# GD32VW553x register map
File version: 1.0
CPU: other RISC-V, little endian, no MPU, FPU
Registers are 32-bit, read-write, reset 0x0 unless marked. A register's access mark holds for its fields unless they carry their own. Offsets are from the block's base; [hi:lo] are bit positions; {n}, {i} and the like mark numbered series.

## FMC — Flash memory controller
Base 0x40022000
0x04 KEY wo — Unlock key register
  [31:0] KEY — FMC_CTL unlock register
0x08 OBKEY wo — Option byte unlock key register
  [31:0] OBKEY — These bits are only be written by software
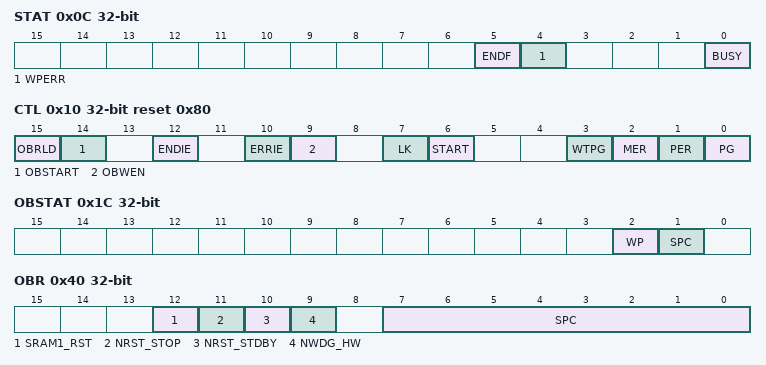
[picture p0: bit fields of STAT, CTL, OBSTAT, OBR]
0x0C STAT access per field — Status register
  [5] ENDF rw — End of operation flag bit
  [4] WPERR rw — Erase / Program protection error flag bit
  [0] BUSY ro — The flash is busy bit
0x10 CTL access per field reset 0x80 — Control register
  [15] OBRLD rw — Option byte reload bit
  [14] OBSTART rw — Option bytes modification start bit
  [12] ENDIE rw — End of operation interrupt enable bit
  [10] ERRIE rw — Error interrupt enable bit
  [9] OBWEN rw — FMC option byte registers write enable bit
  [7] LK ro — FMC_CTL lock bit
  [6] START ro — Send erase command to FMC
  [3] WTPG rw — WIFI trim program command bit
  [2] MER rw — Main flash mass erase command bit
  [1] PER rw — Main flash page erase command bit
  [0] PG rw — Main flash program command bit
0x14 ADDR wo — Address register
  [31:0] ADDR — Flash erase / program command address bits
0x1C OBSTAT ro — Option byte status register
  [2] WP — Write/erase protection state, EFFUSE config 32k write protection
  [1] SPC — Security protection level 1 state
0x40 OBR — Option byte register
  [12] SRAM1_RST — SRAM1 reset enable bit
  [11] NRST_STOP — Vcore domain Stop entry reset option status bit
  [10] NRST_STDBY — Vcore domain Standby entry reset option status bit
  [9] NWDG_HW — IWDG option byte
  [7:0] SPC — Option byte security protection value
0x44 OBUSER — Option byte user value register
  [31:0] USER — Option byte USER value
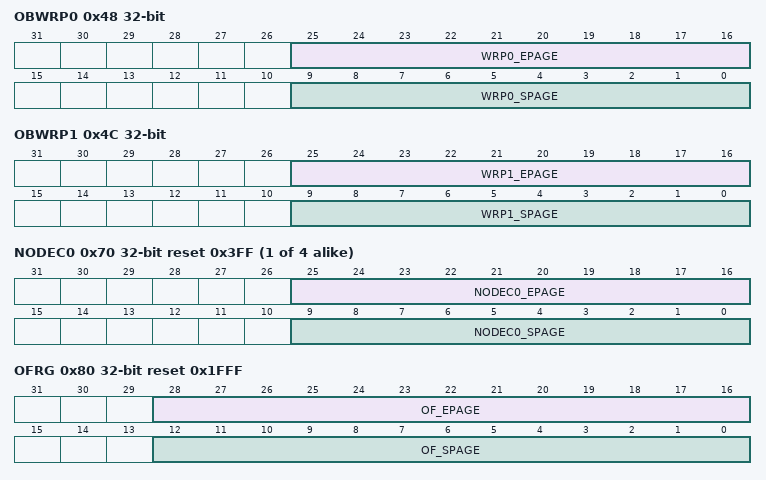
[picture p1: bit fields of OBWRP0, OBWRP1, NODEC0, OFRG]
0x48 OBWRP0 — Option byte write protection area register 0
  [25:16] WRP0_EPAGE — End page of write protection area 0
  [9:0] WRP0_SPAGE — Start page of write protection area 0
0x4C OBWRP1 — Option byte write protection area register 1
  [25:16] WRP1_EPAGE — End page of write protection area 1
  [9:0] WRP1_SPAGE — Start page of write protection area 1
{0x70+4i} NODEC{i} reset 0x3FF (i=0..3) — NO RTDEC region register {i}
  [25:16] NODEC{i}_EPAGE — End page of NODEC region {i}
  [9:0] NODEC{i}_SPAGE — Start page of NODEC region {i}
0x80 OFRG reset 0x1FFF — Offset region register
  [28:16] OF_EPAGE — End page of offset region
  [12:0] OF_SPAGE — Start page of offset region
0x84 OFVR — Offset value register
  [12:0] OF_VALUE — Offset value
0x100 PID0 ro — Product ID0 register
  [31:0] PID0 — Product reserved ID code register
0x104 PID1 ro — Product ID1 register
  [31:0] PID1 — Product reserved ID code register
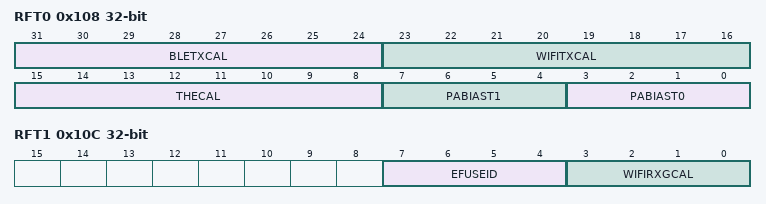
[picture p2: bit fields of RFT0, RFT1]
0x108 RFT0 ro — RF Trim register 0
  [31:24] BLETXCAL — BLE transmit power calibration value
  [23:16] WIFITXCAL — WIFI transmit power calibration value
  [15:8] THECAL — Thermal meter calibration value
  [7:4] PABIAST1 — The PA bias fine tune value
  [3:0] PABIAST0 — The PA(Power Amplifier) bias coarse tune value
0x10C RFT1 ro — RF Trim register 1
  [7:4] EFUSEID — The EFUSE version ID
  [3:0] WIFIRXGCAL — The WIFI receive gain calibration value
{0x200+4i} WFT{i} (i=0..15) — WIFI Trim register {i}
  [31:0] WIFI_TRIM — After the system is reset, it is loaded from the flash

## FWDGT — free watchdog timer
Base 0x40003000
0x00 CTL wo — Control register
  [15:0] CMD — Key value
0x04 PSC — Prescaler register
  [2:0] PSC — Prescaler divider
0x08 RLD reset 0xFFF — Reload register
  [11:0] RLD — Free watchdog timer counter reload value
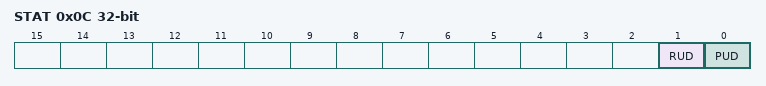
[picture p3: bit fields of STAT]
0x0C STAT ro — Status register
  [1] RUD — Free watchdog timer counter reload value update
  [0] PUD — Free watchdog timer prescaler value update

## GPIOA — General-purpose I/Os
Base 0x40020000
Same registers: GPIOB 0x40020400, GPIOC 0x40020800
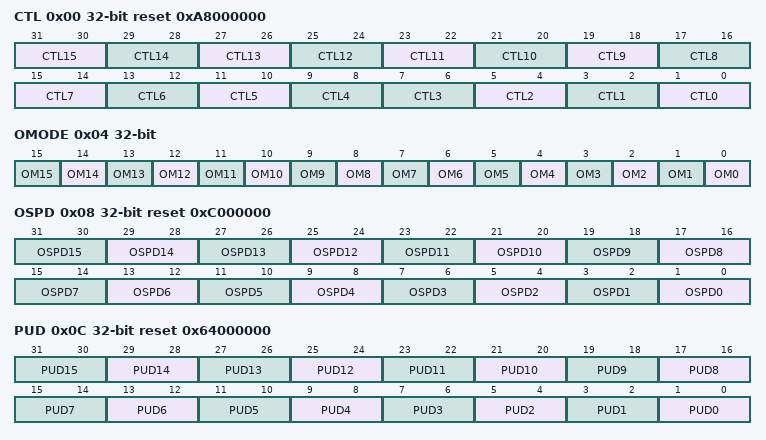
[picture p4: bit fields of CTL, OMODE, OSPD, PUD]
0x00 CTL reset 0xA8000000 — GPIO port control register
  [2n+1:2n] CTL{n} (n=7..15) — Port x configuration bits (x = {n})
  [13:12] CTL6 — Port x configuration bits (x = 6 )
  [11:10] CTL5 — Port x configuration bits (x = 5)
  [9:8] CTL4 — Port x configuration bits (x = 4 )
  [2n+1:2n] CTL{n} (n=0..3) — Port x configuration bits (x = {n})
0x04 OMODE — GPIO port output mode register
  [n] OM{n} (n=0..15) — Port {n} output mode bit
0x08 OSPD reset 0xC000000 — GPIO port output speed register
  [2n+1:2n] OSPD{n} (n=0..15) — Port {n} output max speed bits
0x0C PUD reset 0x64000000 — GPIO port pull-up/pull-down register
  [2n+1:2n] PUD{n} (n=0..15) — Port {n} pull-up or pull-down bits
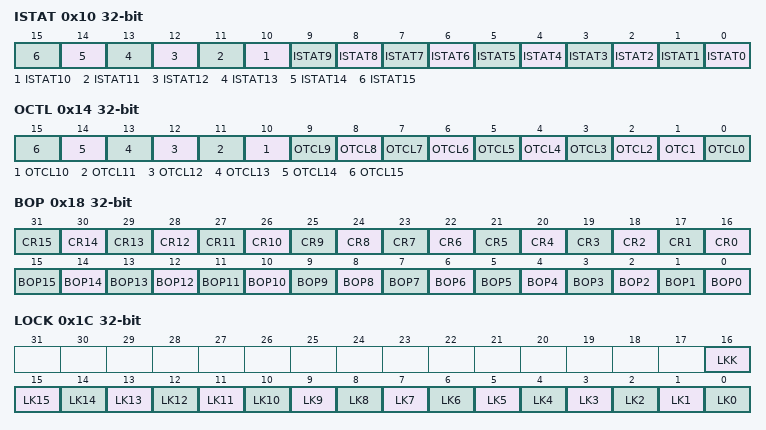
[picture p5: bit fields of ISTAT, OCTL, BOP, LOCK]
0x10 ISTAT ro — GPIO port input status register
  [n] ISTAT{n} (n=0..15) — Port input status (y = {n})
0x14 OCTL — Port output control register
  [n] OTCL{n} (n=2..15) — Pin output control(y=0..15)
  [1] OTC1 — Pin output control(y=0..15)
  [0] OTCL0 — Pin output control(y=0..15)
0x18 BOP wo — GPIO port bit operate register
  [n+16] CR{n} (n=0..15) — Port Clear bit {n}
  [n] BOP{n} (n=0..15) — Port Set bit {n}
0x1C LOCK — GPIO port configuration lock register
  [16] LKK — Lock sequence key
  [n] LK{n} (n=0..15) — Port Lock bit {n}
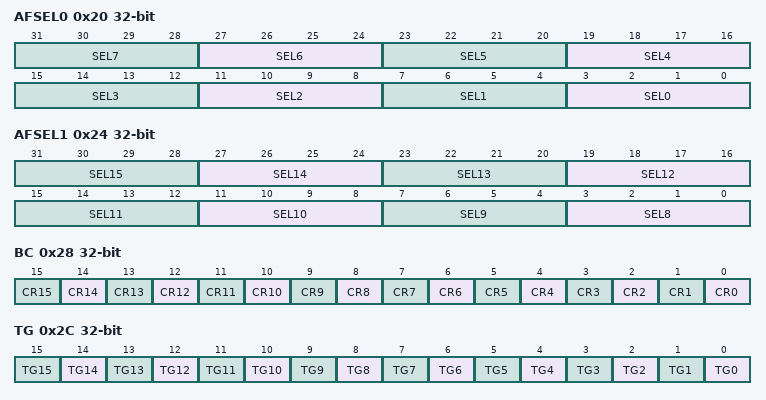
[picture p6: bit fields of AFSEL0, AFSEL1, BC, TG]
0x20 AFSEL0 — GPIO alternate function selected register 0
  [4n+3:4n] SEL{n} (n=0..7) — Port {n} alternate function selected
0x24 AFSEL1 — GPIO alternate function selected register 1
  [4n-29:4n-32] SEL{n} (n=8..15) — Port {n} alternate function selected
0x28 BC wo — Bit clear register
  [n] CR{n} (n=0..15) — Port cleat bit
0x2C TG wo — Port bit toggle register
  [n] TG{n} (n=0..15) — Port toggle bit
